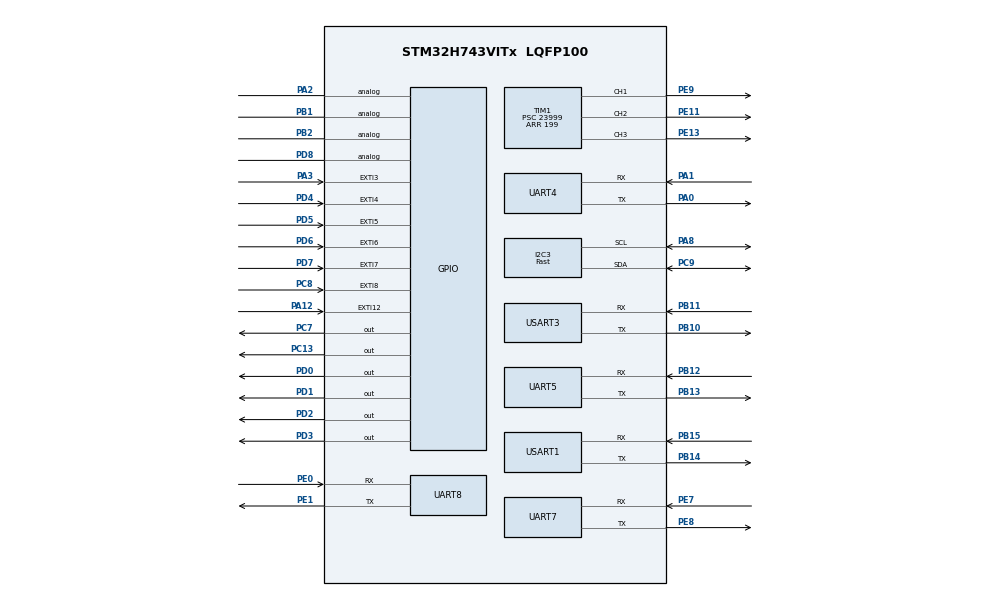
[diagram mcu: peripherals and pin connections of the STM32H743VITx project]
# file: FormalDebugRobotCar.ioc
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Dma.Request0=USART3_TX
Dma.Request1=USART3_RX
Dma.Request2=UART8_RX
Dma.UART8_RX.2.Direction=DMA_PERIPH_TO_MEMORY
Dma.UART8_RX.2.EventEnable=DISABLE
Dma.UART8_RX.2.FIFOMode=DMA_FIFOMODE_DISABLE
Dma.UART8_RX.2.Instance=DMA1_Stream2
Dma.UART8_RX.2.MemDataAlignment=DMA_MDATAALIGN_BYTE
Dma.UART8_RX.2.MemInc=DMA_MINC_ENABLE
Dma.UART8_RX.2.Mode=DMA_CIRCULAR
Dma.UART8_RX.2.PeriphDataAlignment=DMA_PDATAALIGN_BYTE
Dma.UART8_RX.2.PeriphInc=DMA_PINC_DISABLE
Dma.UART8_RX.2.Polarity=HAL_DMAMUX_REQ_GEN_RISING
Dma.UART8_RX.2.Priority=DMA_PRIORITY_LOW
Dma.UART8_RX.2.RequestNumber=1
Dma.UART8_RX.2.SignalID=NONE
Dma.UART8_RX.2.SyncEnable=DISABLE
Dma.UART8_RX.2.SyncPolarity=HAL_DMAMUX_SYNC_NO_EVENT
Dma.UART8_RX.2.SyncRequestNumber=1
Dma.UART8_RX.2.SyncSignalID=NONE
Dma.USART3_RX.1.Direction=DMA_PERIPH_TO_MEMORY
Dma.USART3_RX.1.EventEnable=DISABLE
Dma.USART3_RX.1.FIFOMode=DMA_FIFOMODE_DISABLE
Dma.USART3_RX.1.Instance=DMA1_Stream1
Dma.USART3_RX.1.MemDataAlignment=DMA_MDATAALIGN_BYTE
Dma.USART3_RX.1.MemInc=DMA_MINC_ENABLE
Dma.USART3_RX.1.Mode=DMA_NORMAL
Dma.USART3_RX.1.PeriphDataAlignment=DMA_PDATAALIGN_BYTE
Dma.USART3_RX.1.PeriphInc=DMA_PINC_DISABLE
Dma.USART3_RX.1.Polarity=HAL_DMAMUX_REQ_GEN_RISING
Dma.USART3_RX.1.Priority=DMA_PRIORITY_LOW
Dma.USART3_RX.1.RequestNumber=1
Dma.USART3_RX.1.SignalID=NONE
Dma.USART3_RX.1.SyncEnable=DISABLE
Dma.USART3_RX.1.SyncPolarity=HAL_DMAMUX_SYNC_NO_EVENT
Dma.USART3_RX.1.SyncRequestNumber=1
Dma.USART3_RX.1.SyncSignalID=NONE
Dma.USART3_TX.0.Direction=DMA_MEMORY_TO_PERIPH
Dma.USART3_TX.0.EventEnable=DISABLE
Dma.USART3_TX.0.FIFOMode=DMA_FIFOMODE_DISABLE
Dma.USART3_TX.0.Instance=DMA1_Stream0
Dma.USART3_TX.0.MemDataAlignment=DMA_MDATAALIGN_BYTE
Dma.USART3_TX.0.MemInc=DMA_MINC_ENABLE
Dma.USART3_TX.0.Mode=DMA_NORMAL
Dma.USART3_TX.0.PeriphDataAlignment=DMA_PDATAALIGN_BYTE
Dma.USART3_TX.0.PeriphInc=DMA_PINC_DISABLE
Dma.USART3_TX.0.Polarity=HAL_DMAMUX_REQ_GEN_RISING
Dma.USART3_TX.0.Priority=DMA_PRIORITY_LOW
Dma.USART3_TX.0.RequestNumber=1
Dma.USART3_TX.0.SignalID=NONE
Dma.USART3_TX.0.SyncEnable=DISABLE
Dma.USART3_TX.0.SyncPolarity=HAL_DMAMUX_SYNC_NO_EVENT
Dma.USART3_TX.0.SyncRequestNumber=1
Dma.USART3_TX.0.SyncSignalID=NONE
I2C3.I2C_Speed_Mode=I2C_Fast
I2C3.Timing=0x00B03FDB
Mcu.Family=STM32H7
Mcu.Name=STM32H743VITx
Mcu.Package=LQFP100
NVIC.DMA1_Stream0_IRQn=true\:1\:1\:true\:false\:true\:false\:true
NVIC.DMA1_Stream1_IRQn=true\:1\:1\:true\:false\:true\:false\:true
NVIC.DMA1_Stream2_IRQn=true\:1\:2\:true\:false\:true\:false\:true
NVIC.EXTI15_10_IRQn=true\:2\:0\:true\:false\:true\:true\:true
NVIC.EXTI3_IRQn=true\:2\:0\:true\:false\:true\:true\:true
NVIC.EXTI4_IRQn=true\:2\:1\:true\:false\:true\:true\:true
NVIC.EXTI9_5_IRQn=true\:2\:1\:true\:false\:true\:true\:true
NVIC.PriorityGroup=NVIC_PRIORITYGROUP_2
NVIC.TIM2_IRQn=true\:0\:1\:true\:false\:true\:true\:true
NVIC.TIM3_IRQn=true\:0\:2\:true\:false\:true\:true\:true
NVIC.TIM4_IRQn=true\:0\:3\:true\:false\:true\:true\:true
NVIC.UART4_IRQn=true\:1\:0\:true\:false\:true\:true\:true
NVIC.UART5_IRQn=true\:3\:0\:true\:false\:true\:true\:true
NVIC.UART8_IRQn=true\:1\:2\:true\:false\:true\:true\:true
NVIC.USART1_IRQn=true\:1\:0\:true\:false\:true\:true\:true
NVIC.USART3_IRQn=true\:1\:1\:true\:false\:true\:true\:true
PA0.GPIO_Speed=GPIO_SPEED_FREQ_VERY_HIGH
PA0.Mode=Asynchronous
PA0.Signal=UART4_TX
PA1.GPIO_Speed=GPIO_SPEED_FREQ_VERY_HIGH
PA1.Mode=Asynchronous
PA1.Signal=UART4_RX
PA12.GPIO_ModeDefaultEXTI=GPIO_MODE_IT_RISING_FALLING
PA12.Signal=GPXTI12
PA13\ (JTMS/SWDIO).Mode=Serial_Wire
PA13\ (JTMS/SWDIO).Signal=DEBUG_JTMS-SWDIO
PA14\ (JTCK/SWCLK).Mode=Serial_Wire
PA14\ (JTCK/SWCLK).Signal=DEBUG_JTCK-SWCLK
PA2.Signal=GPIO_Analog
PA3.GPIO_ModeDefaultEXTI=GPIO_MODE_IT_RISING_FALLING
PA3.Signal=GPXTI3
PA8.GPIO_PuPd=GPIO_PULLUP
PA8.GPIO_Speed=GPIO_SPEED_FREQ_VERY_HIGH
PA8.Mode=I2C
PA8.Signal=I2C3_SCL
PB1.Signal=GPIO_Analog
PB10.GPIO_Speed=GPIO_SPEED_FREQ_VERY_HIGH
PB10.Mode=Asynchronous
PB10.Signal=USART3_TX
PB11.GPIO_Speed=GPIO_SPEED_FREQ_VERY_HIGH
PB11.Mode=Asynchronous
PB11.Signal=USART3_RX
PB12.GPIO_Speed=GPIO_SPEED_FREQ_VERY_HIGH
PB12.Mode=Asynchronous
PB12.Signal=UART5_RX
PB13.GPIO_Speed=GPIO_SPEED_FREQ_VERY_HIGH
PB13.Mode=Asynchronous
PB13.Signal=UART5_TX
PB14.GPIO_Speed=GPIO_SPEED_FREQ_VERY_HIGH
PB14.Mode=Asynchronous
PB14.Signal=USART1_TX
PB15.GPIO_Speed=GPIO_SPEED_FREQ_VERY_HIGH
PB15.Mode=Asynchronous
PB15.Signal=USART1_RX
PB2.Signal=GPIO_Analog
PC13.PinAttribute=Free
PC13.PinState=GPIO_PIN_RESET
PC13.Signal=GPIO_Output
PC7.GPIO_PuPd=GPIO_PULLUP
PC7.PinState=GPIO_PIN_SET
PC7.Signal=GPIO_Output
PC8.GPIO_ModeDefaultEXTI=GPIO_MODE_IT_FALLING
PC8.GPIO_PuPd=GPIO_PULLUP
PC8.Signal=GPXTI8
PC9.GPIO_PuPd=GPIO_PULLUP
PC9.GPIO_Speed=GPIO_SPEED_FREQ_VERY_HIGH
PC9.Mode=I2C
PC9.Signal=I2C3_SDA
PD0.GPIO_Speed=GPIO_SPEED_FREQ_HIGH
PD0.PinState=GPIO_PIN_RESET
PD0.Signal=GPIO_Output
PD1.GPIO_Speed=GPIO_SPEED_FREQ_HIGH
PD1.PinState=GPIO_PIN_RESET
PD1.Signal=GPIO_Output
PD2.GPIO_Speed=GPIO_SPEED_FREQ_HIGH
PD2.PinState=GPIO_PIN_RESET
PD2.Signal=GPIO_Output
PD3.GPIO_Speed=GPIO_SPEED_FREQ_HIGH
PD3.PinState=GPIO_PIN_RESET
PD3.Signal=GPIO_Output
PD4.GPIO_ModeDefaultEXTI=GPIO_MODE_IT_FALLING
PD4.GPIO_PuPd=GPIO_PULLUP
PD4.Signal=GPXTI4
PD5.GPIO_ModeDefaultEXTI=GPIO_MODE_IT_FALLING
PD5.GPIO_PuPd=GPIO_PULLUP
PD5.Signal=GPXTI5
PD6.GPIO_ModeDefaultEXTI=GPIO_MODE_IT_FALLING
PD6.GPIO_PuPd=GPIO_PULLUP
PD6.Signal=GPXTI6
PD7.GPIO_ModeDefaultEXTI=GPIO_MODE_IT_FALLING
PD7.GPIO_PuPd=GPIO_PULLUP
PD7.Signal=GPXTI7
PD8.Signal=GPIO_Analog
PE0.GPIO_Speed=GPIO_SPEED_FREQ_VERY_HIGH
PE0.Mode=Asynchronous
PE0.Signal=UART8_RX
PE1.GPIO_Speed=GPIO_SPEED_FREQ_VERY_HIGH
PE1.Mode=Asynchronous
PE1.Signal=UART8_TX
PE11.GPIO_Speed=GPIO_SPEED_FREQ_MEDIUM
PE11.Signal=S_TIM1_CH2
PE13.GPIO_Speed=GPIO_SPEED_FREQ_MEDIUM
PE13.Signal=S_TIM1_CH3
PE7.GPIO_Speed=GPIO_SPEED_FREQ_VERY_HIGH
PE7.Mode=Asynchronous
PE7.Signal=UART7_RX
PE8.GPIO_Speed=GPIO_SPEED_FREQ_VERY_HIGH
PE8.Mode=Asynchronous
PE8.Signal=UART7_TX
PE9.GPIO_Speed=GPIO_SPEED_FREQ_MEDIUM
PE9.Signal=S_TIM1_CH1
PH0-OSC_IN\ (PH0).Mode=HSE-External-Oscillator
PH0-OSC_IN\ (PH0).Signal=RCC_OSC_IN
PH1-OSC_OUT\ (PH1).Mode=HSE-External-Oscillator
PH1-OSC_OUT\ (PH1).Signal=RCC_OSC_OUT
ProjectManager.HeapSize=0x200
ProjectManager.StackSize=0x400
ProjectManager.TargetToolchain=MDK-ARM V5.27
RCC.ADCFreq_Value=480000000
RCC.APB1Freq_Value=120000000
RCC.APB2Freq_Value=120000000
RCC.APB3Freq_Value=120000000
RCC.APB4Freq_Value=120000000
RCC.CortexFreq_Value=480000000
RCC.D1PPRE=RCC_APB3_DIV2
RCC.D2PPRE1=RCC_APB1_DIV2
RCC.D2PPRE2=RCC_APB2_DIV2
RCC.D3PPRE=RCC_APB4_DIV2
RCC.DIVM1=5
RCC.DIVM2=5
RCC.DIVM3=5
RCC.DIVN1=192
RCC.DIVN2=192
RCC.DIVN3=192
RCC.EnbaleCSS=true
RCC.HCLKFreq_Value=240000000
RCC.HPRE=RCC_HCLK_DIV2
RCC.PLL1_VCI_Range-AdvancedSettings=RCC_PLL1VCIRANGE_2
RCC.PLL3_VCI_Range-AdvancedSettings=RCC_PLL3VCIRANGE_3
RCC.PLLSourceVirtual=RCC_PLLSOURCE_HSE
RCC.SPI123CLockSelection=RCC_SPI123CLKSOURCE_CLKP
RCC.SYSCLKFreq_VALUE=480000000
RCC.SYSCLKSource=RCC_SYSCLKSOURCE_PLLCLK
RCC.USBFreq_Value=480000000
SH.S_TIM1_CH1.0=TIM1_CH1,PWM Generation1 CH1
SH.S_TIM1_CH2.0=TIM1_CH2,PWM Generation2 CH2
SH.S_TIM1_CH3.0=TIM1_CH3,PWM Generation3 CH3
TIM1.Channel-PWM\ Generation1\ CH1=TIM_CHANNEL_1
TIM1.Channel-PWM\ Generation2\ CH2=TIM_CHANNEL_2
TIM1.Channel-PWM\ Generation3\ CH3=TIM_CHANNEL_3
TIM1.Period=199
TIM1.Prescaler=23999
TIM1.Pulse-PWM\ Generation1\ CH1=10
TIM2.Period=99
TIM2.Prescaler=23999
TIM3.Period=99
TIM3.Prescaler=23999
TIM4.Period=4999
TIM4.Prescaler=23999
USART1.VirtualMode-Asynchronous=VM_ASYNC
USART3.VirtualMode-Asynchronous=VM_ASYNC
VP_TIM1_VS_ClockSourceINT.Mode=Internal
VP_TIM2_VS_ClockSourceINT.Mode=Internal
VP_TIM3_VS_ClockSourceINT.Mode=Internal
VP_TIM4_VS_ClockSourceINT.Mode=Internal
board=custom

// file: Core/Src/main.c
/* USER CODE BEGIN Header */
/**
  ******************************************************************************
  * @file           : main.c
  * @brief          : Main program body
  ******************************************************************************
  * @attention
  *
  * <h2><center>&copy; Copyright (c) 2021 STMicroelectronics.
  * All rights reserved.</center></h2>
  *
  * This software component is licensed by ST under BSD 3-Clause license,
  * the "License"; You may not use this file except in compliance with the
  * License. You may obtain a copy of the License at:
  *                        opensource.org/licenses/BSD-3-Clause
  *
  ******************************************************************************
  */
/* USER CODE END Header */
#include "main.h"
#include "dma.h"
#include "i2c.h"
#include "tim.h"
#include "usart.h"
#include "gpio.h"

/* USER CODE BEGIN Includes */
#include "UserMain.h"
/* USER CODE END Includes */

void SystemClock_Config(void);

int main(void)
{

  /* MCU Configuration--------------------------------------------------------*/

  /* Reset of all peripherals, Initializes the Flash interface and the Systick. */
  HAL_Init();

  /* Configure the system clock */
  SystemClock_Config();

  /* Initialize all configured peripherals */
  MX_GPIO_Init();
  MX_DMA_Init();
  MX_UART8_Init();
  MX_USART1_UART_Init();
  MX_USART3_UART_Init();
  MX_TIM2_Init();
  MX_TIM3_Init();
  MX_TIM4_Init();
  MX_TIM1_Init();
  MX_I2C3_Init();
  MX_UART4_Init();
  MX_UART5_Init();
  MX_UART7_Init();
  /* USER CODE BEGIN 2 */
	UserInit();
  /* USER CODE END 2 */

  /* Infinite loop */
  /* USER CODE BEGIN WHILE */
  while (1)
  {
		UserLoop();
    /* USER CODE END WHILE */

  }
}

void SystemClock_Config(void)
{
  RCC_OscInitTypeDef RCC_OscInitStruct = {0};
  RCC_ClkInitTypeDef RCC_ClkInitStruct = {0};

  /** Supply configuration update enable
  */
  HAL_PWREx_ConfigSupply(PWR_LDO_SUPPLY);
  /** Configure the main internal regulator output voltage
  */
  __HAL_PWR_VOLTAGESCALING_CONFIG(PWR_REGULATOR_VOLTAGE_SCALE0);

  while(!__HAL_PWR_GET_FLAG(PWR_FLAG_VOSRDY)) {}
  /** Initializes the RCC Oscillators according to the specified parameters
  * in the RCC_OscInitTypeDef structure.
  */
  RCC_OscInitStruct.OscillatorType = RCC_OSCILLATORTYPE_HSE;
  RCC_OscInitStruct.HSEState = RCC_HSE_ON;
  RCC_OscInitStruct.PLL.PLLState = RCC_PLL_ON;
  RCC_OscInitStruct.PLL.PLLSource = RCC_PLLSOURCE_HSE;
  RCC_OscInitStruct.PLL.PLLM = 5;
  RCC_OscInitStruct.PLL.PLLN = 192;
  RCC_OscInitStruct.PLL.PLLP = 2;
  RCC_OscInitStruct.PLL.PLLQ = 2;
  RCC_OscInitStruct.PLL.PLLR = 2;
  RCC_OscInitStruct.PLL.PLLRGE = RCC_PLL1VCIRANGE_2;
  RCC_OscInitStruct.PLL.PLLVCOSEL = RCC_PLL1VCOWIDE;
  RCC_OscInitStruct.PLL.PLLFRACN = 0;
  if (HAL_RCC_OscConfig(&RCC_OscInitStruct) != HAL_OK)
  {
    Error_Handler();
  }
  /** Initializes the CPU, AHB and APB buses clocks
  */
  RCC_ClkInitStruct.ClockType = RCC_CLOCKTYPE_HCLK|RCC_CLOCKTYPE_SYSCLK
                              |RCC_CLOCKTYPE_PCLK1|RCC_CLOCKTYPE_PCLK2
                              |RCC_CLOCKTYPE_D3PCLK1|RCC_CLOCKTYPE_D1PCLK1;
  RCC_ClkInitStruct.SYSCLKSource = RCC_SYSCLKSOURCE_PLLCLK;
  RCC_ClkInitStruct.SYSCLKDivider = RCC_SYSCLK_DIV1;
  RCC_ClkInitStruct.AHBCLKDivider = RCC_HCLK_DIV2;
  RCC_ClkInitStruct.APB3CLKDivider = RCC_APB3_DIV2;
  RCC_ClkInitStruct.APB1CLKDivider = RCC_APB1_DIV2;
  RCC_ClkInitStruct.APB2CLKDivider = RCC_APB2_DIV2;
  RCC_ClkInitStruct.APB4CLKDivider = RCC_APB4_DIV2;

  if (HAL_RCC_ClockConfig(&RCC_ClkInitStruct, FLASH_LATENCY_4) != HAL_OK)
  {
    Error_Handler();
  }
  /** Enables the Clock Security System
  */
  HAL_RCC_EnableCSS();
}

void Error_Handler(void)
{
  /* USER CODE BEGIN Error_Handler_Debug */
  /* User can add his own implementation to report the HAL error return state */
  __disable_irq();
  while (1)
  {
		HAL_GPIO_WritePin(LED_GPIO_PORT, LED_GPIO_PIN, GPIO_PIN_SET);  //֮����Ը�Ϊ������
  }
  /* USER CODE END Error_Handler_Debug */
}

/************************ (C) COPYRIGHT STMicroelectronics *****END OF FILE****/
